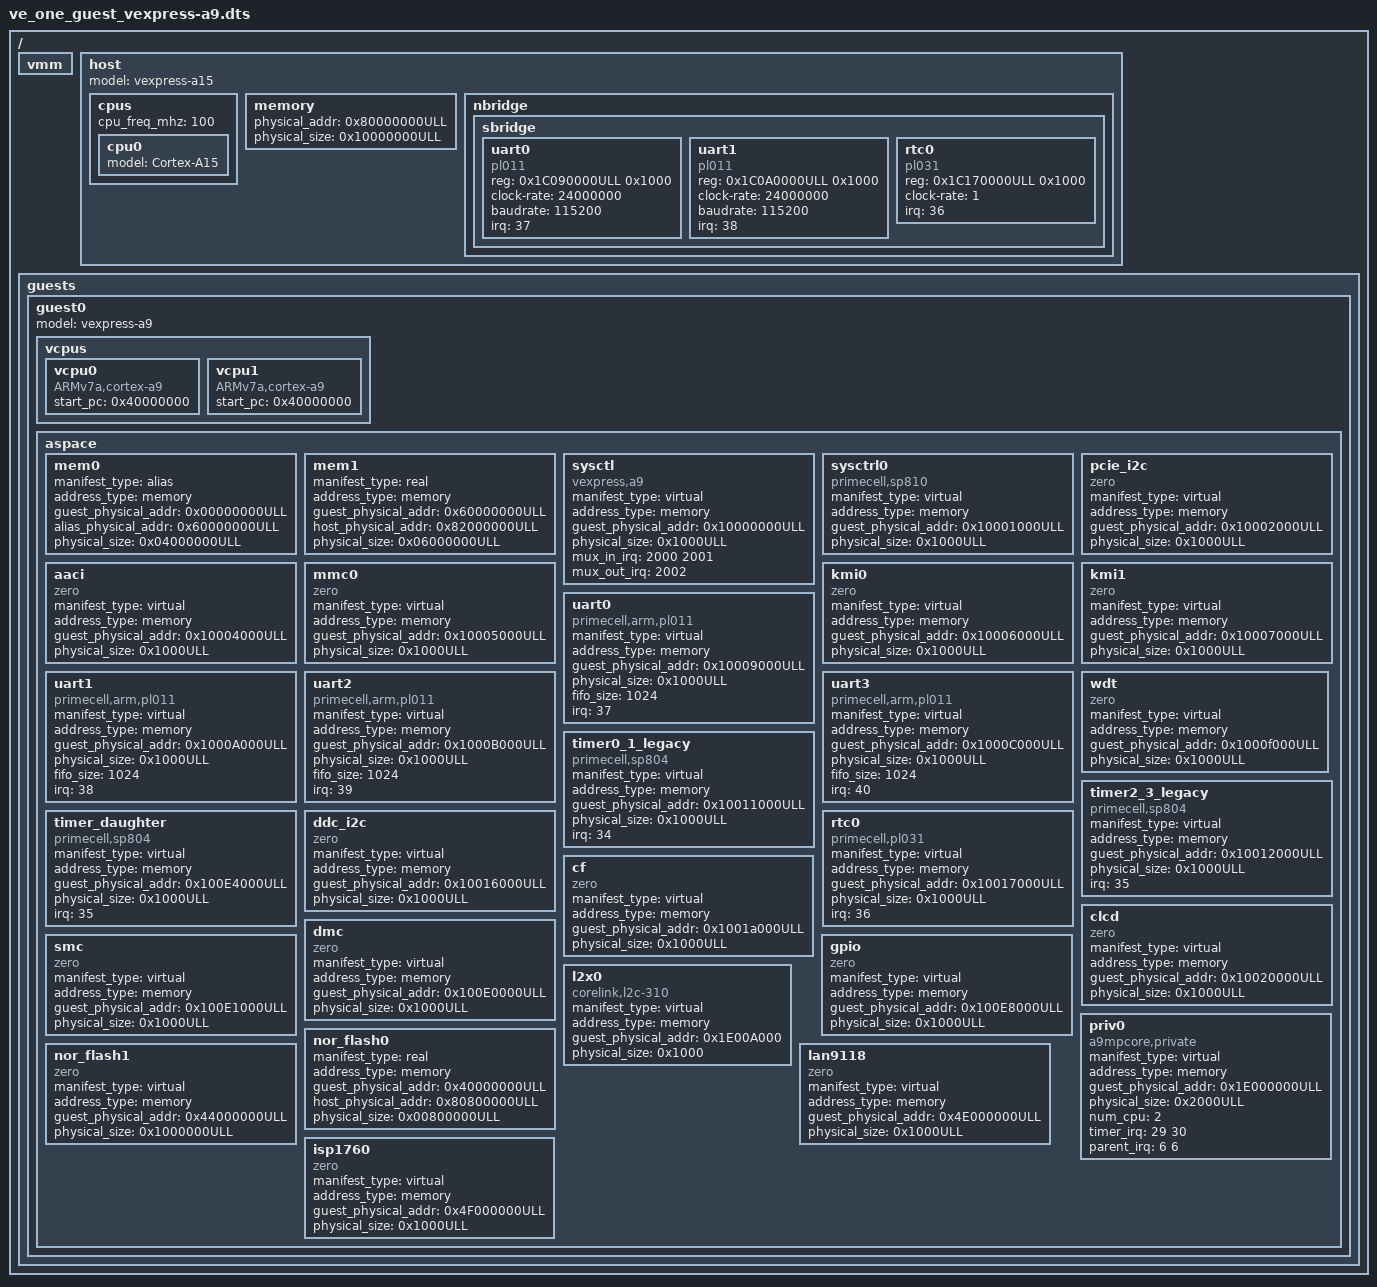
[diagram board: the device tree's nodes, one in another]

/dts-v1/;

/ {
	vmm {
		#address-cells = <1>;
		#size-cells = <0>;
	};

	host {
		#address-cells = <2>;
		#size-cells = <1>;
		model = "vexpress-a15";
		device_type = "host";
		
		cpus {
			#address-cells = <1>;
			#size-cells = <0>;
			cpu_freq_mhz = <100>;

			cpu0 {
				device_type = "cpu";
				model = "Cortex-A15";
			};
		};

		memory {
			/* NOTE: By default QEMU will only proivde 128 MB 
			 * unless specified by "-m" option. If you have
			 * X MB then we will be able to access only first
			 * X MB starting at physical_addr.
			 */
			physical_addr = <0x80000000ULL>;
			physical_size = <0x10000000ULL>; /* 256 MB */
		};

		nbridge {
			#address-cells = <1>;
			#size-cells = <0>;
		
			sbridge {
				#address-cells = <1>;
				#size-cells = <0>;
		
				uart0 {
			      		device_type = "serial";
			      		compatible = "pl011";
			      		reg = <0x1C090000ULL 0x1000>;
					clock-rate = <24000000>;
			      		baudrate = <115200>;
					irq = <37>;
				};

				uart1 {
			      		device_type = "serial";
			      		compatible = "pl011";
			      		reg = <0x1C0A0000ULL 0x1000>;
					clock-rate = <24000000>;
			      		baudrate = <115200>;
					irq = <38>;
				};

				rtc0 {
			      		device_type = "rtc";
			      		compatible = "pl031";
			      		reg = <0x1C170000ULL 0x1000>;
					clock-rate = <1>;
					irq = <36>;
				};
			};
		};
	};

	guests {
		#address-cells = <1>;
		#size-cells = <0>;

		guest0 {
			#address-cells = <1>;
			#size-cells = <0>;
			model = "vexpress-a9";
			device_type = "guest";

			vcpus {
				#address-cells = <1>;
				#size-cells = <0>;

				vcpu0 {
					device_type = "vcpu";
					compatible = "ARMv7a,cortex-a9";
					start_pc = <0x40000000>;
				};

				vcpu1 {
					device_type = "vcpu";
					compatible = "ARMv7a,cortex-a9";
					start_pc = <0x40000000>;
				};
			};
			
			aspace {
				#address-cells = <1>;
				#size-cells = <0>;

				/* Assume the REMAP region is mapped to DDR */
				mem0 {
					manifest_type = "alias";
					address_type = "memory";
					guest_physical_addr = <0x00000000ULL>;
					alias_physical_addr = <0x60000000ULL>;
					physical_size = <0x04000000ULL>; /* 64 MB */
					device_type = "ram";
				};

				mem1 {
					manifest_type = "real";
					address_type = "memory";
					guest_physical_addr = <0x60000000ULL>;
					host_physical_addr = <0x82000000ULL>;
					physical_size = <0x06000000ULL>; /* 96 MB */
					device_type = "ram";
				};

				sysctl {
					manifest_type = "virtual";
					address_type = "memory";
					guest_physical_addr = <0x10000000ULL>;
					physical_size = <0x1000ULL>;
					device_type = "sys";
					compatible = "vexpress,a9";
					mux_in_irq = <2000 2001>;
					mux_out_irq = <2002>;
				};

				sysctrl0 {
					manifest_type = "virtual";
					address_type = "memory";
					guest_physical_addr = <0x10001000ULL>;
					physical_size = <0x1000ULL>;
					device_type = "sys";
					compatible = "primecell,sp810";
				};

				pcie_i2c { /* No I2C */
					manifest_type = "virtual";
					address_type = "memory";
					guest_physical_addr = <0x10002000ULL>;
					physical_size = <0x1000ULL>;
					device_type = "misc";
					compatible = "zero";
				};

				aaci { /* No Audio Controller */
					manifest_type = "virtual";
					address_type = "memory";
					guest_physical_addr = <0x10004000ULL>;
					physical_size = <0x1000ULL>;
					device_type = "misc";
					compatible = "zero";
				};

				mmc0 { /* No Multimedia Card Interface */
					manifest_type = "virtual";
					address_type = "memory";
					guest_physical_addr = <0x10005000ULL>;
					physical_size = <0x1000ULL>;
					device_type = "misc";
					compatible = "zero";
				};

				kmi0 { /* No Keyboard/Mouse Interface */
					manifest_type = "virtual";
					address_type = "memory";
					guest_physical_addr = <0x10006000ULL>;
					physical_size = <0x1000ULL>;
					device_type = "misc";
					compatible = "zero";
				};

				kmi1 { /* No Keyboard/Mouse Interface */
					manifest_type = "virtual";
					address_type = "memory";
					guest_physical_addr = <0x10007000ULL>;
					physical_size = <0x1000ULL>;
					device_type = "misc";
					compatible = "zero";
				};

				uart0 {
					manifest_type = "virtual";
					address_type = "memory";
					guest_physical_addr = <0x10009000ULL>;
					physical_size = <0x1000ULL>;
					device_type = "serial";
					compatible = "primecell,arm,pl011";
					fifo_size = <1024>;
					irq = <37>;
				};

				uart1 {
					manifest_type = "virtual";
					address_type = "memory";
					guest_physical_addr = <0x1000A000ULL>;
					physical_size = <0x1000ULL>;
					device_type = "serial";
					compatible = "primecell,arm,pl011";
					fifo_size = <1024>;
					irq = <38>;
				};

				uart2 {
					manifest_type = "virtual";
					address_type = "memory";
					guest_physical_addr = <0x1000B000ULL>;
					physical_size = <0x1000ULL>;
					device_type = "serial";
					compatible = "primecell,arm,pl011";
					fifo_size = <1024>;
					irq = <39>;
				};

				uart3 {
					manifest_type = "virtual";
					address_type = "memory";
					guest_physical_addr = <0x1000C000ULL>;
					physical_size = <0x1000ULL>;
					device_type = "serial";
					compatible = "primecell,arm,pl011";
					fifo_size = <1024>;
					irq = <40>;
				};

				wdt { /* No Watch-Dog controller */
					manifest_type = "virtual";
					address_type = "memory";
					guest_physical_addr = <0x1000f000ULL>;
					physical_size = <0x1000ULL>;
					device_type = "misc";
					compatible = "zero";
				};

				timer0_1_legacy {
					manifest_type = "virtual";
					address_type = "memory";
					guest_physical_addr = <0x10011000ULL>;
					physical_size = <0x1000ULL>;
					device_type = "timer";
					compatible = "primecell,sp804";
					irq = <34>;
				};

				timer2_3_legacy {
					manifest_type = "virtual";
					address_type = "memory";
					guest_physical_addr = <0x10012000ULL>;
					physical_size = <0x1000ULL>;
					device_type = "timer";
					compatible = "primecell,sp804";
					irq = <35>;
				};

				timer_daughter {
					manifest_type = "virtual";
					address_type = "memory";
					guest_physical_addr = <0x100E4000ULL>;
					physical_size = <0x1000ULL>;
					device_type = "timer";
					compatible = "primecell,sp804";
					irq = <35>;
				};

				ddc_i2c { /* No I2C */
					manifest_type = "virtual";
					address_type = "memory";
					guest_physical_addr = <0x10016000ULL>;
					physical_size = <0x1000ULL>;
					device_type = "misc";
					compatible = "zero";
				};

				rtc0 {
					manifest_type = "virtual";
					address_type = "memory";
					guest_physical_addr = <0x10017000ULL>;
					physical_size = <0x1000ULL>;
					device_type = "rtc";
					compatible = "primecell,pl031";
					irq = <36>;
				};

				cf { /* No PATA Controller */
					manifest_type = "virtual";
					address_type = "memory";
					guest_physical_addr = <0x1001a000ULL>;
					physical_size = <0x1000ULL>;
					device_type = "misc";
					compatible = "zero";
				};

				clcd { /* No Color LCD */
					manifest_type = "virtual";
					address_type = "memory";
					guest_physical_addr = <0x10020000ULL>;
					physical_size = <0x1000ULL>;
					device_type = "misc";
					compatible = "zero";
				};

				dmc { /* No DMC */
					manifest_type = "virtual";
					address_type = "memory";
					guest_physical_addr = <0x100E0000ULL>;
					physical_size = <0x1000ULL>;
					device_type = "misc";
					compatible = "zero";
				};

				smc { /* No SMC */
					manifest_type = "virtual";
					address_type = "memory";
					guest_physical_addr = <0x100E1000ULL>;
					physical_size = <0x1000ULL>;
					device_type = "misc";
					compatible = "zero";
				};

				gpio { /* No GPIO */
					manifest_type = "virtual";
					address_type = "memory";
					guest_physical_addr = <0x100E8000ULL>;
					physical_size = <0x1000ULL>;
					device_type = "misc";
					compatible = "zero";
				};

				priv0 {
					manifest_type = "virtual";
					address_type = "memory";
					guest_physical_addr = <0x1E000000ULL>;
					physical_size = <0x2000ULL>;
					device_type = "misc";
					num_cpu = <2>;
					compatible = "a9mpcore,private";
					timer_irq = <29 30>;
					parent_irq = <6 6>;
				};

				l2x0 {
					manifest_type = "virtual";
					address_type = "memory";
					guest_physical_addr = <0x1E00A000>;
					physical_size = <0x1000>;
					device_type = "cache";
					compatible = "corelink,l2c-310";
				};

				nor_flash0 {
					manifest_type = "real";
					address_type = "memory";
					guest_physical_addr = <0x40000000ULL>;
					host_physical_addr = <0x80800000ULL>;
					physical_size = <0x00800000ULL>; /* 8 MB */
					device_type = "rom";
				};

				nor_flash1 { /* No Second NOR flash */
					manifest_type = "virtual";
					address_type = "memory";
					guest_physical_addr = <0x44000000ULL>;
					physical_size = <0x1000000ULL>; /* 16 MB */
					device_type = "misc";
					compatible = "zero";
				};

				lan9118 { /* No Ethernet Controller */
					manifest_type = "virtual";
					address_type = "memory";
					guest_physical_addr = <0x4E000000ULL>;
					physical_size = <0x1000ULL>;
					device_type = "misc";
					compatible = "zero";
				};

				isp1760 { /* No USB Controller */
					manifest_type = "virtual";
					address_type = "memory";
					guest_physical_addr = <0x4F000000ULL>;
					physical_size = <0x1000ULL>;
					device_type = "misc";
					compatible = "zero";
				};
			};
		};
	};
};
